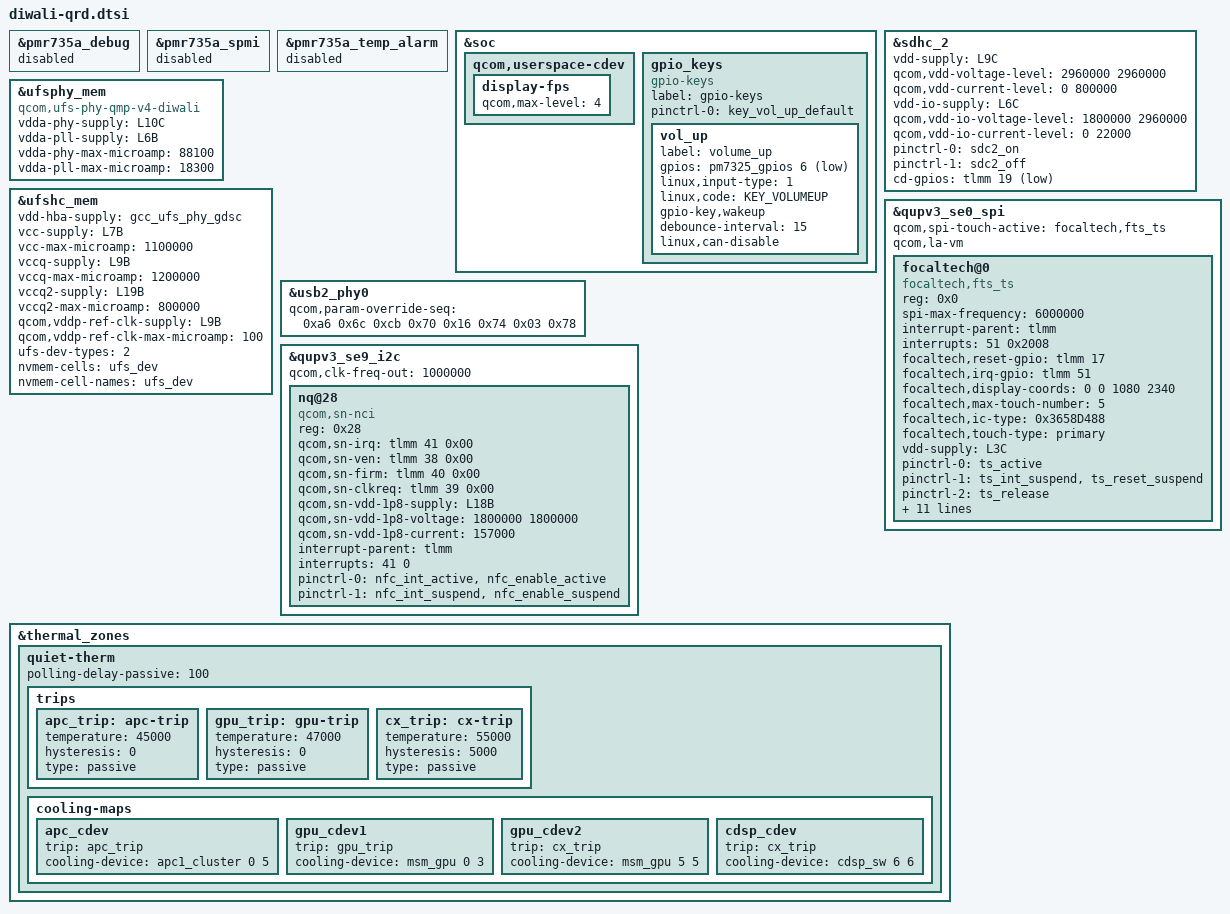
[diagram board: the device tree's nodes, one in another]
#include <dt-bindings/gpio/gpio.h>
#include <dt-bindings/input/input.h>

#include "diwali-pmic-overlay.dtsi"
#include "diwali-thermal-overlay.dtsi"

&pmr735a_debug {
	status = "disabled";
};

&pmr735a_spmi {
	status = "disabled";
};

&pmr735a_temp_alarm {
	status = "disabled";
};

&soc {
	qcom,userspace-cdev {
		display-fps {
			qcom,max-level = <4>;
		};
	};

	gpio_keys {
		compatible = "gpio-keys";
		label = "gpio-keys";

		pinctrl-names = "default";
		pinctrl-0 = <&key_vol_up_default>;

		vol_up {
			label = "volume_up";
			gpios = <&pm7325_gpios 6 GPIO_ACTIVE_LOW>;
			linux,input-type = <1>;
			linux,code = <KEY_VOLUMEUP>;
			gpio-key,wakeup;
			debounce-interval = <15>;
			linux,can-disable;
		};
	};
};

&sdhc_2 {
	status = "ok";
	vdd-supply = <&L9C>;
	qcom,vdd-voltage-level = <2960000 2960000>;
	qcom,vdd-current-level = <0 800000>;

	vdd-io-supply = <&L6C>;
	qcom,vdd-io-voltage-level = <1800000 2960000>;
	qcom,vdd-io-current-level = <0 22000>;

	pinctrl-names = "default", "sleep";
	pinctrl-0 = <&sdc2_on>;
	pinctrl-1 = <&sdc2_off>;

	cd-gpios = <&tlmm 19 GPIO_ACTIVE_LOW>;
};

&ufsphy_mem {
	compatible = "qcom,ufs-phy-qmp-v4-diwali";

	vdda-phy-supply = <&L10C>;
	vdda-pll-supply = <&L6B>;
	vdda-phy-max-microamp = <88100>;
	vdda-pll-max-microamp = <18300>;

	status = "ok";
};

&ufshc_mem {
	vdd-hba-supply = <&gcc_ufs_phy_gdsc>;

	vcc-supply = <&L7B>;
	vcc-max-microamp = <1100000>;

	vccq-supply = <&L9B>;
	vccq-max-microamp = <1200000>;

	vccq2-supply = <&L19B>;
	vccq2-max-microamp = <800000>;

	qcom,vddp-ref-clk-supply = <&L9B>;
	qcom,vddp-ref-clk-max-microamp = <100>;

	/*
	 * ufs-dev-types and nvmem entries are for ufs device
	 * identification using nvmem interface. Use number of
	 * ufs devices supported for ufs-dev-types, and nvmem handle
	 * added by pmic for sdam register.
	 */
	ufs-dev-types = <2>;
	nvmem-cells = <&ufs_dev>;
	nvmem-cell-names = "ufs_dev";

	status = "ok";
};

&qupv3_se0_spi {
	#address-cells = <1>;
	#size-cells = <0>;

	status = "ok";

	qcom,spi-touch-active = "focaltech,fts_ts";
	qcom,la-vm;

	focaltech@0 {
		compatible = "focaltech,fts_ts";
		reg = <0x0>;
		spi-max-frequency = <6000000>;
		interrupt-parent = <&tlmm>;
		interrupts = <51 0x2008>;
		focaltech,reset-gpio = <&tlmm 17 0x00>;
		focaltech,irq-gpio = <&tlmm 51 0x2008>;
		focaltech,display-coords = <0 0 1080 2340>;
		focaltech,max-touch-number = <5>;
		focaltech,ic-type = <0x3658D488>;
		focaltech,touch-type = "primary";

		vdd-supply = <&L3C>;

		pinctrl-names = "pmx_ts_active", "pmx_ts_suspend", "pmx_ts_release";
		pinctrl-0 = <&ts_active>;
		pinctrl-1 = <&ts_int_suspend &ts_reset_suspend>;
		pinctrl-2 = <&ts_release>;

		focaltech,trusted-touch-mode = "vm_mode";
		focaltech,touch-environment = "pvm";
		focaltech,trusted-touch-type = "primary";
		focaltech,trusted-touch-spi-irq = <566>;
		focaltech,trusted-touch-io-bases = <0x980000 0x910000>;
		focaltech,trusted-touch-io-sizes = <0x1000 0x4000>;
		focaltech,trusted-touch-vm-gpio-list = <&tlmm 0 0 &tlmm 1 0 &tlmm 2 0
						&tlmm 3 0 &tlmm 17 0 &tlmm 51 0x2008>;
	};
};

&usb2_phy0 {
	qcom,param-override-seq = <
			/* override x0 */
			0xa6 0x6c
			/* override x1 */
			0xcb 0x70
			/* override x2 */
			0x16 0x74
			/* override x3 */
			0x03 0x78>;
};

&qupv3_se9_i2c {
	status = "ok";
	qcom,clk-freq-out = <1000000>;
	#address-cells = <1>;
	#size-cells = <0>;
	nq@28 {
		compatible = "qcom,sn-nci";
		reg = <0x28>;
		qcom,sn-irq = <&tlmm 41 0x00>;
		qcom,sn-ven = <&tlmm 38 0x00>;
		qcom,sn-firm = <&tlmm 40 0x00>;
		qcom,sn-clkreq = <&tlmm 39 0x00>;
		qcom,sn-vdd-1p8-supply = <&L18B>;
		qcom,sn-vdd-1p8-voltage = <1800000 1800000>;
		qcom,sn-vdd-1p8-current = <157000>;
		interrupt-parent = <&tlmm>;
		interrupts = <41 0>;
		interrupt-names = "nfc_irq";
		pinctrl-names = "nfc_active", "nfc_suspend";
		pinctrl-0 = <&nfc_int_active &nfc_enable_active>;
		pinctrl-1 = <&nfc_int_suspend &nfc_enable_suspend>;
	};
};

&thermal_zones {
	quiet-therm {
		polling-delay-passive = <100>;

		trips {
			apc_trip:apc-trip {
				temperature = <45000>;
				hysteresis = <0>;
				type = "passive";
			};

			gpu_trip:gpu-trip {
				temperature = <47000>;
				hysteresis = <0>;
				type = "passive";
			};

			cx_trip:cx-trip {
				temperature = <55000>;
				hysteresis = <5000>;
				type = "passive";
			};
		};

		cooling-maps {
			apc_cdev {
				trip = <&apc_trip>;
				cooling-device = <&apc1_cluster 0 5>;
			};

			gpu_cdev1 {
				trip = <&gpu_trip>;
				/* Limit freq to 540000000 Hz*/
				cooling-device = <&msm_gpu 0 3>;
			};

			gpu_cdev2 {
				trip = <&cx_trip>;
				/* Limit freq to 285000000 Hz*/
				cooling-device = <&msm_gpu 5 5>;
			};

			cdsp_cdev {
				trip = <&cx_trip>;
				cooling-device = <&cdsp_sw 6 6>;
			};
		};
	};
};

